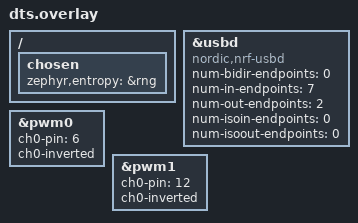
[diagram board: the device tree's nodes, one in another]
/ {
	chosen {
		/*
		 * In some default configurations within the nRF Connect SDK,
		 * e.g. on nRF52840 and nRF9160, the chosen zephyr,entropy node
		 * is &cryptocell. This devicetree overlay ensures that default
		 * is overridden wherever it is set, as this application uses
		 * the RNG node for entropy exclusively.
		 */
		zephyr,entropy = &rng;
	};
};

&usbd {
	compatible = "nordic,nrf-usbd";
	status = "okay";
	num-bidir-endpoints = <0>;
	num-in-endpoints = <7>;
	num-out-endpoints = <2>;
	num-isoin-endpoints = <0>;
	num-isoout-endpoints = <0>;
};

&pwm0 {
	status = "okay";
	ch0-pin = <6>;
	ch0-inverted;
	/delete-property/ ch1-pin;
	/delete-property/ ch1-inverted;
	/delete-property/ ch2-pin;
	/delete-property/ ch2-inverted;
};

&pwm1 {
	status = "okay";
	ch0-pin = <12>;
	ch0-inverted;
};
